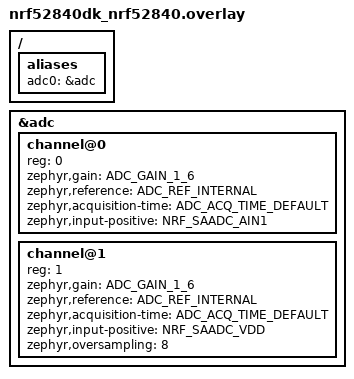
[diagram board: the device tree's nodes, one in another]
/*
 * Copyright (c) 2024 Centro de Inovacao EDGE
 *
 * SPDX-License-Identifier: Apache-2.0
 */

/ {
	aliases {
		adc0 = &adc;
	};
};

&adc {
	#address-cells = <1>;
	#size-cells = <0>;

	channel@0 {
		reg = <0>;
		zephyr,gain = "ADC_GAIN_1_6";
		zephyr,reference = "ADC_REF_INTERNAL";
		zephyr,acquisition-time = <ADC_ACQ_TIME_DEFAULT>;
		zephyr,input-positive = <NRF_SAADC_AIN1>; /* P0.03 */
	};

	channel@1 {
		reg = <1>;
		zephyr,gain = "ADC_GAIN_1_6";
		zephyr,reference = "ADC_REF_INTERNAL";
		zephyr,acquisition-time = <ADC_ACQ_TIME_DEFAULT>;
		zephyr,input-positive = <NRF_SAADC_VDD>;
		zephyr,oversampling = <8>;
	};
};
